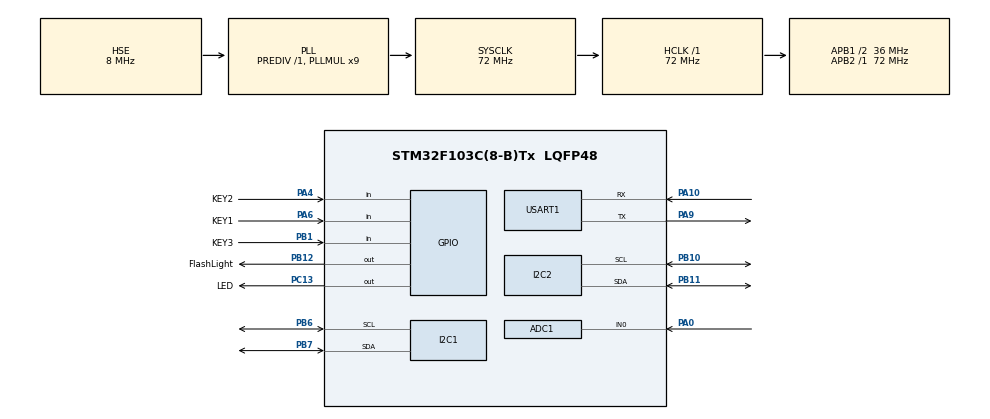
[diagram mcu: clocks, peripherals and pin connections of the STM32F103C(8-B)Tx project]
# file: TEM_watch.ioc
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ADC1.Channel-0\#ChannelRegularConversion=ADC_CHANNEL_0
ADC1.NbrOfConversion=1
ADC1.NbrOfConversionFlag=1
ADC1.Rank-0\#ChannelRegularConversion=1
ADC1.SamplingTime-0\#ChannelRegularConversion=ADC_SAMPLETIME_7CYCLES_5
ADC1.master=1
I2C1.I2C_Mode=I2C_Fast
I2C2.I2C_Mode=I2C_Fast
Mcu.Family=STM32F1
Mcu.Name=STM32F103C(8-B)Tx
Mcu.Package=LQFP48
NVIC.PriorityGroup=NVIC_PRIORITYGROUP_4
NVIC.TIM1_UP_IRQn=true\:0\:0\:false\:false\:true\:true\:true\:true
PA0-WKUP.Signal=ADCx_IN0
PA10.Mode=Asynchronous
PA10.Signal=USART1_RX
PA13.Mode=Serial_Wire
PA13.Signal=SYS_JTMS-SWDIO
PA14.Mode=Serial_Wire
PA14.Signal=SYS_JTCK-SWCLK
PA4.GPIO_Label=KEY2
PA4.GPIO_PuPd=GPIO_PULLUP
PA4.Signal=GPIO_Input
PA6.GPIO_Label=KEY1
PA6.GPIO_PuPd=GPIO_PULLUP
PA6.Signal=GPIO_Input
PA9.Mode=Asynchronous
PA9.Signal=USART1_TX
PB1.GPIO_Label=KEY3
PB1.GPIO_PuPd=GPIO_PULLUP
PB1.Signal=GPIO_Input
PB10.Mode=I2C
PB10.Signal=I2C2_SCL
PB11.Mode=I2C
PB11.Signal=I2C2_SDA
PB12.GPIO_Label=FlashLight
PB12.GPIO_ModeDefaultOutputPP=GPIO_MODE_OUTPUT_PP
PB12.Signal=GPIO_Output
PB6.Mode=I2C
PB6.Signal=I2C1_SCL
PB7.Mode=I2C
PB7.Signal=I2C1_SDA
PC13-TAMPER-RTC.GPIO_Label=LED
PC13-TAMPER-RTC.PinState=GPIO_PIN_SET
PC13-TAMPER-RTC.Signal=GPIO_Output
PC14-OSC32_IN.Mode=LSE-External-Oscillator
PC14-OSC32_IN.Signal=RCC_OSC32_IN
PC15-OSC32_OUT.Mode=LSE-External-Oscillator
PC15-OSC32_OUT.Signal=RCC_OSC32_OUT
PD0-OSC_IN.Mode=HSE-External-Oscillator
PD0-OSC_IN.Signal=RCC_OSC_IN
PD1-OSC_OUT.Mode=HSE-External-Oscillator
PD1-OSC_OUT.Signal=RCC_OSC_OUT
ProjectManager.HeapSize=0x200
ProjectManager.StackSize=0x400
ProjectManager.TargetToolchain=CMake
RCC.ADCPresc=RCC_ADCPCLK2_DIV6
RCC.AHBFreq_Value=72000000
RCC.APB1CLKDivider=RCC_HCLK_DIV2
RCC.APB1Freq_Value=36000000
RCC.APB1TimFreq_Value=72000000
RCC.APB2Freq_Value=72000000
RCC.APB2TimFreq_Value=72000000
RCC.HCLKFreq_Value=72000000
RCC.PLLMUL=RCC_PLL_MUL9
RCC.PLLSourceVirtual=RCC_PLLSOURCE_HSE
RCC.RTCClockSelection=RCC_RTCCLKSOURCE_LSE
RCC.SYSCLKFreq_VALUE=72000000
RCC.SYSCLKSource=RCC_SYSCLKSOURCE_PLLCLK
RCC.USBFreq_Value=72000000
RTC.AutoPrediv=RTC_AUTO_1_SECOND
RTC.Date=14
RTC.Month=RTC_MONTH_AUGUST
RTC.WeekDay=RTC_WEEKDAY_FRIDAY
SH.ADCx_IN0.0=ADC1_IN0,IN0
TIM1.AutoReloadPreload=TIM_AUTORELOAD_PRELOAD_ENABLE
TIM1.Period=4999
TIM1.Prescaler=71
USART1.VirtualMode=VM_ASYNC
VP_RTC_No_RTC_Output.Mode=RTC_OUT_NO
VP_RTC_VS_RTC_Activate.Mode=RTC_Enabled
VP_TIM1_VS_ClockSourceINT.Mode=Internal
board=custom

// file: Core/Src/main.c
/* USER CODE BEGIN Header */
/**
  ******************************************************************************
  * @file           : main.c
  * @brief          : Main program body
  ******************************************************************************
  * @attention
  *
  * Copyright (c) 2026 STMicroelectronics.
  * All rights reserved.
  *
  * This software is licensed under terms that can be found in the LICENSE file
  * in the root directory of this software component.
  * If no LICENSE file comes with this software, it is provided AS-IS.
  *
  ******************************************************************************
  */
/* USER CODE END Header */
#include "main.h"
#include "adc.h"
#include "i2c.h"
#include "rtc.h"
#include "tim.h"
#include "usart.h"
#include "gpio.h"

/* USER CODE BEGIN Includes */
#include"menu.h"
#include"oled.h"
#include"Key.h"

/* USER CODE END Includes */

void SystemClock_Config(void);

/* USER CODE BEGIN 0 */

extern volatile uint8_t mpu_sample_flag;

//TIM1中断回调函数,用于定时采样MPU6050数据,每5ms调用一次
void HAL_TIM_PeriodElapsedCallback(TIM_HandleTypeDef *htim)
{
    if (htim->Instance == TIM1)
    {
        mpu_sample_flag = 1; // 设置标志位，表示可以采样MPU6050数据
    }
}

/* USER CODE END 0 */

int main(void)
{

  /* MCU Configuration--------------------------------------------------------*/

  /* Reset of all peripherals, Initializes the Flash interface and the Systick. */
  HAL_Init();

  /* Configure the system clock */
  SystemClock_Config();

  /* Initialize all configured peripherals */
  MX_GPIO_Init();
  MX_I2C1_Init();
  MX_USART1_UART_Init();
  MX_RTC_Init();
  MX_TIM1_Init();
  MX_I2C2_Init();
  MX_ADC1_Init();
  /* USER CODE BEGIN 2 */
  HAL_TIM_Base_Start_IT(&htim1);

  OLED_Init();
  HAL_GPIO_WritePin(LED_GPIO_Port, LED_Pin, GPIO_PIN_RESET);

  /* USER CODE END 2 */

  /* Infinite loop */
  /* USER CODE BEGIN WHILE */

   Show_Setting_clock();
   Show_Clock_UI();

  //OLED_DrawBitmap(42,8,44,44,Frame);
  //OLED_DrawBitmap(48,16,32,32,picture0_32x32);

  while (1)
  {
    Menu_UI_Update(); //时钟界面更新
    Key_Scan();

    /* USER CODE END WHILE */

  }
}

void SystemClock_Config(void)
{
  RCC_OscInitTypeDef RCC_OscInitStruct = {0};
  RCC_ClkInitTypeDef RCC_ClkInitStruct = {0};
  RCC_PeriphCLKInitTypeDef PeriphClkInit = {0};

  /** Initializes the RCC Oscillators according to the specified parameters
  * in the RCC_OscInitTypeDef structure.
  */
  RCC_OscInitStruct.OscillatorType = RCC_OSCILLATORTYPE_HSE|RCC_OSCILLATORTYPE_LSE;
  RCC_OscInitStruct.HSEState = RCC_HSE_ON;
  RCC_OscInitStruct.HSEPredivValue = RCC_HSE_PREDIV_DIV1;
  RCC_OscInitStruct.LSEState = RCC_LSE_ON;
  RCC_OscInitStruct.HSIState = RCC_HSI_ON;
  RCC_OscInitStruct.PLL.PLLState = RCC_PLL_ON;
  RCC_OscInitStruct.PLL.PLLSource = RCC_PLLSOURCE_HSE;
  RCC_OscInitStruct.PLL.PLLMUL = RCC_PLL_MUL9;
  if (HAL_RCC_OscConfig(&RCC_OscInitStruct) != HAL_OK)
  {
    Error_Handler();
  }

  /** Initializes the CPU, AHB and APB buses clocks
  */
  RCC_ClkInitStruct.ClockType = RCC_CLOCKTYPE_HCLK|RCC_CLOCKTYPE_SYSCLK
                              |RCC_CLOCKTYPE_PCLK1|RCC_CLOCKTYPE_PCLK2;
  RCC_ClkInitStruct.SYSCLKSource = RCC_SYSCLKSOURCE_PLLCLK;
  RCC_ClkInitStruct.AHBCLKDivider = RCC_SYSCLK_DIV1;
  RCC_ClkInitStruct.APB1CLKDivider = RCC_HCLK_DIV2;
  RCC_ClkInitStruct.APB2CLKDivider = RCC_HCLK_DIV1;

  if (HAL_RCC_ClockConfig(&RCC_ClkInitStruct, FLASH_LATENCY_2) != HAL_OK)
  {
    Error_Handler();
  }
  PeriphClkInit.PeriphClockSelection = RCC_PERIPHCLK_RTC|RCC_PERIPHCLK_ADC;
  PeriphClkInit.RTCClockSelection = RCC_RTCCLKSOURCE_LSE;
  PeriphClkInit.AdcClockSelection = RCC_ADCPCLK2_DIV6;
  if (HAL_RCCEx_PeriphCLKConfig(&PeriphClkInit) != HAL_OK)
  {
    Error_Handler();
  }
}

void Error_Handler(void)
{
  __disable_irq();
  while (1)
  {
  }
}
